# ATSAM4SP32A device description
Architecture: CORTEX-M4; Family: SAM4; Series: SAM4SP
Registers are 32-bit, read-write, no defined reset value unless marked. A register's access mark holds for its fields unless they carry their own. Offsets are from the block's base; [hi:lo] are bit positions; {n}, {i} and the like mark numbered series; 'fields as' and 'values as' point back to an identical list.

## ACC — Analog Comparator Controller
Instances: ACC 0x40040000
0x00 ACC_CR wo — Control Register
  [0] SWRST — SoftWare ReSeT
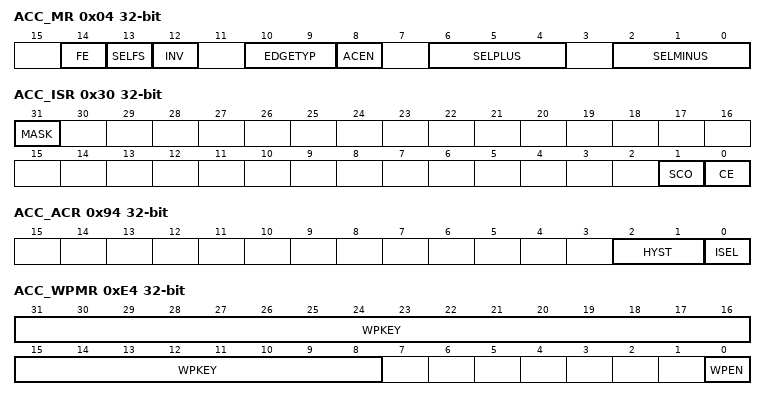
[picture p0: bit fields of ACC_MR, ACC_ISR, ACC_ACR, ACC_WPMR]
0x04 ACC_MR — Mode Register
  [14] FE — Fault Enable
    0=DIS (the FAULT output is tied to 0.); 1=EN (the FAULT output is driven by the signal defined by SELFS.)
  [13] SELFS — SELection of Fault Source
    0=CF (the CF flag is used to drive the FAULT output.); 1=OUTPUT (the output of the Analog Comparator flag is used to drive the FAULT output.)
  [12] INV — INVert comparator output
    0=DIS (Analog Comparator output is directly processed.); 1=EN (Analog Comparator output is inverted prior to being processed.)
  [10:9] EDGETYP — EDGE TYPe
    0=RISING (only rising edge of comparator output); 1=FALLING (falling edge of comparator output); 2=ANY (any edge of comparator output)
  [8] ACEN — Analog Comparator ENable
    0=DIS (Analog Comparator Disabled.); 1=EN (Analog Comparator Enabled.)
  [6:4] SELPLUS — SELection for PLUS comparator input
    {v}=AD{v} (Select AD{v}) (v=0..7)
  [2:0] SELMINUS — SELection for MINUS comparator input
    0=TS (SelectTS); 1=ADVREF (Select ADVREF); 2=DAC0 (Select DAC0); 3=DAC1 (Select DAC1); {v}=AD{v-4} (Select AD{v-4}) (v=4..7)
0x24 ACC_IER wo — Interrupt Enable Register
  [0] CE — Comparison Edge
0x28 ACC_IDR wo — Interrupt Disable Register
  [0] CE — Comparison Edge
0x2C ACC_IMR ro — Interrupt Mask Register
  [0] CE — Comparison Edge
0x30 ACC_ISR ro — Interrupt Status Register
  [31] MASK
  [1] SCO — Synchronized Comparator Output
  [0] CE — Comparison Edge
0x94 ACC_ACR — Analog Control Register
  [2:1] HYST — HYSTeresis selection
  [0] ISEL — Current SELection
    0=LOPW (low power option.); 1=HISP (high speed option.)
0xE4 ACC_WPMR — Write Protect Mode Register
  [31:8] WPKEY — Write Protect KEY
  [0] WPEN — Write Protect Enable
0xE8 ACC_WPSR ro — Write Protect Status Register
  [0] WPROTERR — Write PROTection ERRor

## CHIPID — Chip Identifier
Instances: CHIPID 0x400E0740
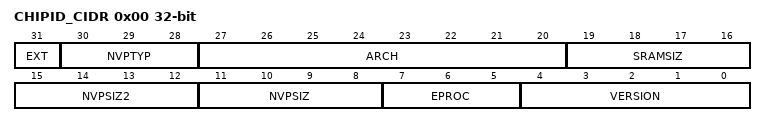
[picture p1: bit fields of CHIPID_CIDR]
0x00 CHIPID_CIDR ro — Chip ID Register
  [31] EXT — Extension Flag
  [30:28] NVPTYP — Nonvolatile Program Memory Type
    0=ROM; 1=ROMLESS (ROMless or on-chip Flash); 2=FLASH (Embedded Flash Memory); 3=ROM_FLASH (ROM and Embedded Flash MemoryNVPSIZ is ROM size NVPSIZ2 is Flash size); 4=SRAM (SRAM emulating ROM)
  [27:20] ARCH — Architecture Identifier
    25=AT91SAM9xx Series; 41=AT91SAM9XExx Series; 52=AT91x34 Series; 55=CAP7 (CAP7 Series); 57=CAP9 (CAP9 Series); 59=CAP11 (CAP11 Series); 60=CM4P (CM4P Series); 64=AT91x40 Series; 66=AT91x42 Series; 85=AT91x55 Series; 96=AT91SAM7Axx Series; 97=AT91SAM7AQxx Series; 99=AT91x63 Series; 100=SAM4CxxC (SAM4CxC Series (100-pin version)); 101=SAM4MxxC Series (100-pin version); 112=AT91SAM7Sxx Series; 113=AT91SAM7XCxx Series; 114=AT91SAM7SExx Series; 115=AT91SAM7Lxx Series; 117=AT91SAM7Xxx Series; 118=AT91SAM7SLxx Series; 128=SAM3UxC Series (100-pin version); 129=SAM3UxE Series (144-pin version); 131=SAM3AxC Series (100-pin version); 132=SAM3XxC Series (100-pin version); 133=SAM3XxE Series (144-pin version); 134=SAM3XxG Series (208/217-pin version); 136=SAM3SxASeries (48-pin version); 136=SAM4SxA Series (48-pin version); 137=SAM3SxB Series (64-pin version); 137=SAM4SxB Series (64-pin version); 138=SAM3SxC Series (100-pin version); 138=SAM4SxC Series (100-pin version); 146=AT91x92 Series; 147=SAM3NxA Series (48-pin version); 148=SAM3NxB Series (64-pin version); 149=SAM3NxC Series (100-pin version); 153=SAM3SDxB Series (64-pin version); 154=SAM3SDxC Series (100-pin version); 165=SAM5A; 176=SAM4LxA Series (48-pin version); 177=SAM4LxB Series (64-pin version); 178=SAM4LxC Series (100-pin version); 240=AT75Cxx Series
  [19:16] SRAMSIZ — Internal SRAM Size
    0=_48K (48 Kbytes); 1=_192K (192 Kbytes); 2=_2K (2 Kbytes); 3=_6K (6 Kbytes); 4=_24K (24 Kbytes); 5=_4K (4 Kbytes); 6=_80K (80 Kbytes); 7=_160K (160 Kbytes); 8=_8K (8 Kbytes); 9=_16K (16 Kbytes); 10=_32K (32 Kbytes); 11=_64K (64 Kbytes); 12=_128K (128 Kbytes); 13=_256K (256 Kbytes); 14=_96K (96 Kbytes); 15=_512K (512 Kbytes)
  [15:12] NVPSIZ2 — Second Nonvolatile Program Memory Size
    0=NONE; 1=_8K (8 Kbytes); 2=_16K (16 Kbytes); 3=_32K (32 Kbytes); 5=_64K (64 Kbytes); 7=_128K (128 Kbytes); 9=_256K (256 Kbytes); 10=_512K (512 Kbytes); 12=_1024K (1024 Kbytes); 14=_2048K (2048 Kbytes)
  [11:8] NVPSIZ — Nonvolatile Program Memory Size
    values as NVPSIZ2
  [7:5] EPROC — Embedded Processor
    1=ARM946ES; 2=ARM7TDMI; 3=CM3 (Cortex-M3); 4=ARM920T; 5=ARM926EJS; 6=CA5 (Cortex-A5); 7=CM4 (Cortex-M4)
  [4:0] VERSION — Version of the Device
0x04 CHIPID_EXID ro — Chip ID Extension Register
  [31:0] EXID — Chip ID Extension
